# LRFDTRC register map
Vendor: Texas Instruments
Peripheral module from a debugger description file (folder CC23x0R5).
Registers are 32-bit, read-write, reset 0x0 unless marked. A register's access mark holds for its fields unless they carry their own. Offsets are as the file gives them; lines under a group give offsets from that group; [hi:lo] are bit positions; {n}, {i} and the like mark numbered series; 'fields as' and 'values as' point back to an identical list; <NAME> marks a mode.

## LRFDTRC
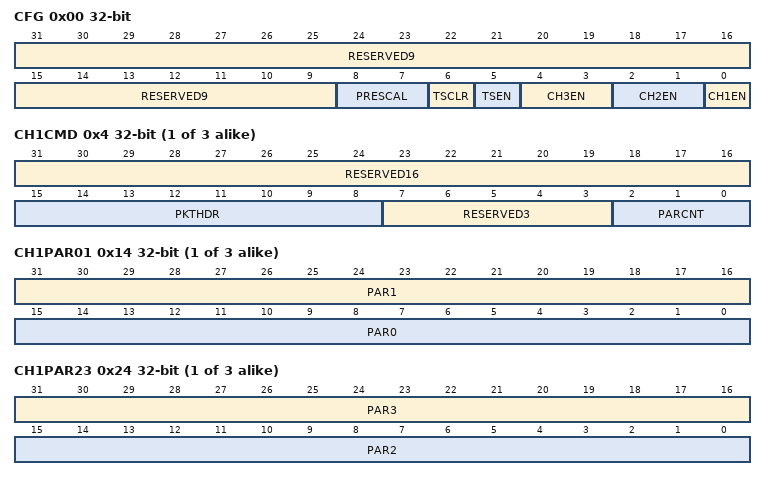
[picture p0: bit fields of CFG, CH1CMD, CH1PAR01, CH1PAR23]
0x00 CFG access per field — Internal. Only to be used through TI provided API.
  [31:9] RESERVED9 ro — Internal. Only to be used through TI provided API.
  [8:7] PRESCAL rw — Internal. Only to be used through TI provided API.
    {v}=DIV{v+1} (Internal. Only to be used through TI provided API.) (v=0..3)
  [6] TSCLR wo — Internal. Only to be used through TI provided API.
    1=ONE (Internal. Only to be used through TI provided API.); 0=ZERO (Internal. Only to be used through TI provided API.)
  [5] TSEN rw — Internal. Only to be used through TI provided API.
    1=ON (Internal. Only to be used through TI provided API.); 0=OFF (Internal. Only to be used through TI provided API.)
  [4:3] CH3EN rw — Internal. Only to be used through TI provided API.
    2=TOPSM (Internal. Only to be used through TI provided API.); 1=NORM (Internal. Only to be used through TI provided API.); 0=OFF (Internal. Only to be used through TI provided API.)
  [2:1] CH2EN rw — Internal. Only to be used through TI provided API.
    values as CH3EN
  [0] CH1EN rw — Internal. Only to be used through TI provided API.
    1=NORM (Internal. Only to be used through TI provided API.); 0=OFF (Internal. Only to be used through TI provided API.)
{0x0+4i} CH{i}CMD access per field (i=1..3) — Internal. Only to be used through TI provided API.
  [31:16] RESERVED16 ro — Internal. Only to be used through TI provided API.
  [15:8] PKTHDR rw — Internal. Only to be used through TI provided API.
    255=ALLONES (Internal. Only to be used through TI provided API.); 0=ALLZEROS (Internal. Only to be used through TI provided API.)
  [7:3] RESERVED3 ro — Internal. Only to be used through TI provided API.
  [2:0] PARCNT rw — Internal. Only to be used through TI provided API.
    7=ALLONES (Internal. Only to be used through TI provided API.); 0=ALLZEROS (Internal. Only to be used through TI provided API.)
{0x10+4i} CH{i}PAR01 (i=1..3) — Internal. Only to be used through TI provided API.
  [31:16] PAR1 — Internal. Only to be used through TI provided API.
    0xFFFF=ALLONES (Internal. Only to be used through TI provided API.); 0=ALLZEROS (Internal. Only to be used through TI provided API.)
  [15:0] PAR0 — Internal. Only to be used through TI provided API.
    values as PAR1
{0x20+4i} CH{i}PAR23 (i=1..3) — Internal. Only to be used through TI provided API.
  [31:16] PAR3 — Internal. Only to be used through TI provided API.
    values as CH1PAR01.PAR1
  [15:0] PAR2 — Internal. Only to be used through TI provided API.
    values as CH1PAR01.PAR1
